# MIMXRT1064 register map
Vendor: nxp.com; File version: 1.0
CPU: CM7 r0p1, little endian, MPU, FPU, VTOR, 4 interrupt priority bits
Registers are 32-bit, read-write, reset 0x0 unless marked. A register's access mark holds for its fields unless they carry their own. Offsets are from the block's base; [hi:lo] are bit positions; {n}, {i} and the like mark numbered series; 'fields as' and 'values as' point back to an identical list.

## ADC_ETC
Base 0x403B0000
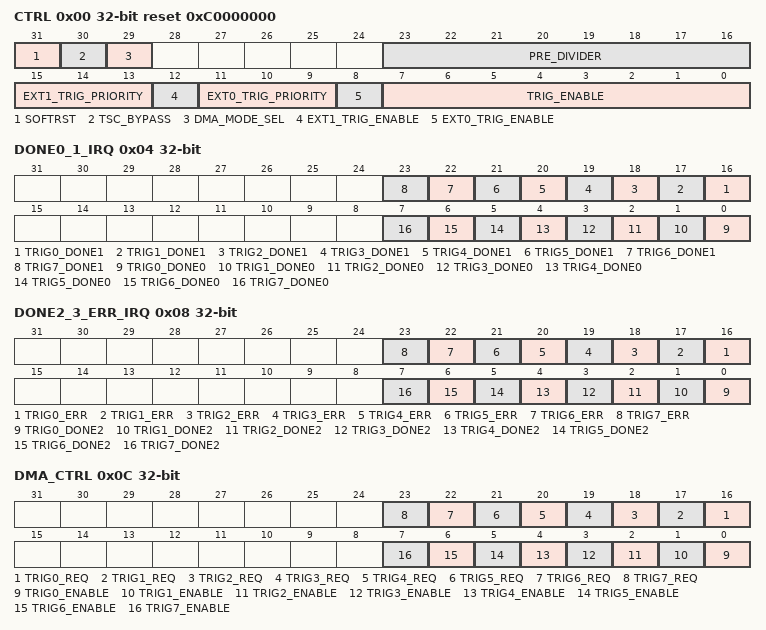
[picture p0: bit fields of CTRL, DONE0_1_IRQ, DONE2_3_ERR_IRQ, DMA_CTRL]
0x00 CTRL reset 0xC0000000 — ADC_ETC Global Control Register
  [31] SOFTRST — Software synchronous reset, active high.
    0=ADC_ETC works normally; 1=All registers inside ADC_ETC will be reset to the default value
  [30] TSC_BYPASS — TSC Bypass To use ADC2, this bit should be cleared.
    0=TSC not bypassed; 1=TSC is bypassed to ADC2, that means TSC will control ADC2 directly
  [29] DMA_MODE_SEL — Select the trigger type of the DMA_REQ.
    0=Trig DMA_REQ with latched signal, REQ will be cleared when ACK and source request cleared; 1=Trig DMA_REQ with pulsed signal, REQ will be cleared by ACK only
  [23:16] PRE_DIVIDER — Pre-divider for trig delay and interval
  [15:13] EXT1_TRIG_PRIORITY — External TSC1 trigger priority, 7 is highest priority, while 0 is lowest.
  [12] EXT1_TRIG_ENABLE — TSC1 TRIG enable register.
    0=disable external TSC1 trigger; 1=enable external TSC1 trigger
  [11:9] EXT0_TRIG_PRIORITY — External TSC0 trigger priority, 7 is highest priority, while 0 is lowest.
  [8] EXT0_TRIG_ENABLE — TSC0 TRIG enable register.
    0=disable external TSC0 trigger; 1=enable external TSC0 trigger
  [7:0] TRIG_ENABLE
    0=disable all 8 external XBAR triggers; 1=enable external XBAR trigger0; 2=enable external XBAR trigger1; 3=enable external XBAR trigger0 and trigger1; 255=enable all 8 external XBAR triggers
0x04 DONE0_1_IRQ write-1-clears — ETC DONE0 and DONE1 IRQ State Register
  [n+16] TRIG{n}_DONE1 write-1-clears (n=0..7) — TRIG{n} done1 interrupt detection.
    0=No TRIG{n}_DONE1 interrupt detected; 1=TRIG{n}_DONE1 interrupt detected
  [n] TRIG{n}_DONE0 write-1-clears (n=0..7) — TRIG{n} done0 interrupt detection.
    0=No TRIG{n}_DONE0 interrupt detected; 1=TRIG{n}_DONE0 interrupt detected
0x08 DONE2_3_ERR_IRQ — ETC DONE_2 and DONE_ERR IRQ State Register
  [n+16] TRIG{n}_ERR (n=0..7) — TRIG{n} error interrupt detection.
    0=No TRIG{n}_ERR interrupt detected; 1=TRIG{n}_ERR interrupt detected
  [n] TRIG{n}_DONE2 write-1-clears (n=0..7) — TRIG{n} done2 interrupt detection.
    0=No TRIG{n}_DONE2 interrupt detected; 1=TRIG{n}_DONE2 interrupt detected
0x0C DMA_CTRL — ETC DMA control Register
  [n+16] TRIG{n}_REQ write-1-clears (n=0..7) — Flag bit for DMA request
    0=TRIG{n}_REQ not detected; 1=TRIG{n}_REQ detected
  [n] TRIG{n}_ENABLE (n=0..7) — Enable DMA request when TRIG{n} done.
    0=TRIG{n} DMA request disabled; 1=TRIG{n} DMA request enabled
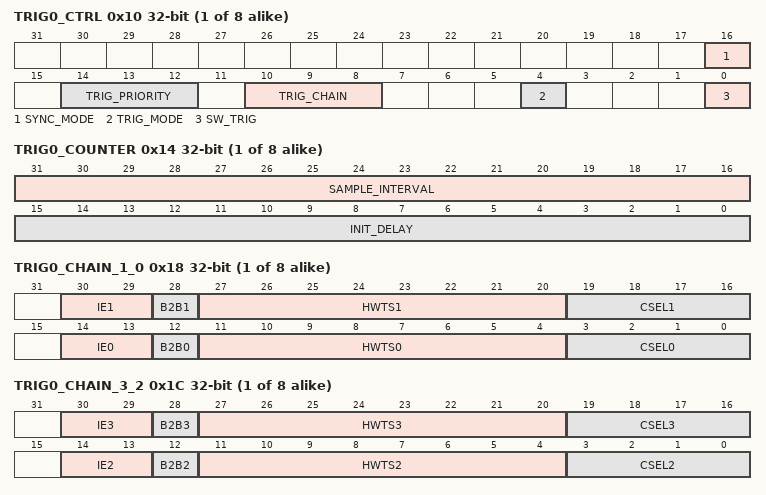
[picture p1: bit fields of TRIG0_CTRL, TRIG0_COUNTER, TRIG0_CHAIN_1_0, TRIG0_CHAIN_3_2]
{0x10+0x28*i} TRIG{i}_CTRL (i=0..7) — ETC_TRIG Control Register
  [16] SYNC_MODE — Trigger synchronization mode selection
    0=Synchronization mode disabled, TRIGa and TRIG(a+4) are triggered independently; 1=Synchronization mode enabled, TRIGa and TRIG(a+4) are triggered by TRIGa source synchronously
  [14:12] TRIG_PRIORITY — External trigger priority, 7 is highest priority, while 0 is lowest
  [10:8] TRIG_CHAIN — The number of segments inside the trigger chain of TRIGa.
    {v}=Trigger chain length is {v+1} (v=0..7)
  [4] TRIG_MODE — Trigger mode selection.
    0=Hardware trigger. The softerware trigger will be ignored.; 1=Software trigger. The hardware trigger will be ignored.
  [0] SW_TRIG — Software trigger. This field is self-clearing.
    0=No software trigger event generated; 1=Software trigger event generated
{0x14+0x28*i} TRIG{i}_COUNTER (i=0..7) — ETC_TRIG Counter Register
  [31:16] SAMPLE_INTERVAL — TRIGGER sampling interval counter
  [15:0] INIT_DELAY — TRIGGER initial delay counter. Initial_delay = (INIT_DELAY+1)*(PRE_DIVIDER+1)*ipg_clk
{0x18+0x28*i} TRIG{i}_CHAIN_1_0 (i=0..7) — ETC_TRIG Chain 0/1 Register
  [30:29] IE1 — Segment 1 done interrupt selection
    0=No interrupt when finished; 1=Generate interrupt on Done0 when Segment 1 finish; 2=Generate interrupt on Done1 when Segment 1 finish; 3=Generate interrupt on Done2 when Segment 1 finish
  [28] B2B1 — Segment 1 B2B
    0=Disable B2B. Wait until delay value defined by TRIG1_COUNTER[SAMPLE_INTERVAL] is reached; 1=Enable B2B. When Segment 0 finished (ADC COCO) then automatically trigger next ADC conversion, no need to wait until interval delay reached.
  [27:20] HWTS1 — Segment 1 HWTS ADC hardware trigger selection
    0=no trigger selected; 1=ADC TRIG0 selected; 2=ADC TRIG1 selected; 4=ADC TRIG2 selected; 8=ADC TRIG3 selected; 16=ADC TRIG4 selected; 32=ADC TRIG5 selected; 64=ADC TRIG6 selected; 128=ADC TRIG7 selected
  [19:16] CSEL1 — ADC channel selection
    {v}=ADC Channel {v} selected (v=0..15)
  [14:13] IE0 — Segment 0 done interrupt selection
    0=No interrupt when finished; 1=Generate interrupt on Done0 when segment 0 finish; 2=Generate interrupt on Done1 when segment 0 finish; 3=Generate interrupt on Done2 when segment 0 finish
  [12] B2B0 — Segment 0 B2B
    0=Disable B2B. Wait until delay value defined by TRIG0_COUNTER[SAMPLE_INTERVAL] is reached; 1=Enable B2B. When Segment 0 finished (ADC COCO) then automatically trigger next ADC conversion, no need to wait until interval delay reached.
  [11:4] HWTS0 — Segment 0 HWTS ADC hardware trigger selection
    values as HWTS1
  [3:0] CSEL0 — ADC channel selection
    {v}=ADC Channel {v} selected (v=0..15)
{0x1C+0x28*i} TRIG{i}_CHAIN_3_2 (i=0..7) — ETC_TRIG Chain 2/3 Register
  [30:29] IE3 — Segment 3 done interrupt selection
    0=No interrupt when finished; 1=Generate interrupt on Done0 when segment 3 finish; 2=Generate interrupt on Done1 when segment 3 finish; 3=Generate interrupt on Done2 when segment 3 finish
  [28] B2B3 — Segment 3 B2B
    0=Disable B2B. Wait until delay value defined by TRIG3_COUNTER[SAMPLE_INTERVAL] is reached; 1=Enable B2B. When Segment 0 finished (ADC COCO) then automatically trigger next ADC conversion, no need to wait until interval delay reached.
  [27:20] HWTS3 — Segment 3 HWTS ADC hardware trigger selection
    values as TRIG0_CHAIN_1_0.HWTS1
  [19:16] CSEL3 — ADC channel selection
    {v}=ADC Channel {v} selected (v=0..15)
  [14:13] IE2 — Segment 2 done interrupt selection
    0=No interrupt when finished; 1=Generate interrupt on Done0 when segment 2 finish; 2=Generate interrupt on Done1 when segment 2 finish; 3=Generate interrupt on Done2 when segment 2 finish
  [12] B2B2 — Segment 2 B2B
    0=Disable B2B. Wait until delay value defined by TRIG2_COUNTER[SAMPLE_INTERVAL] is reached; 1=Enable B2B. When Segment 0 finished (ADC COCO) then automatically trigger next ADC conversion, no need to wait until interval delay reached.
  [11:4] HWTS2 — Segment 2 HWTS ADC hardware trigger selection
    values as TRIG0_CHAIN_1_0.HWTS1
  [3:0] CSEL2 — ADC channel selection
    {v}=ADC Channel {v} selected (v=0..15)
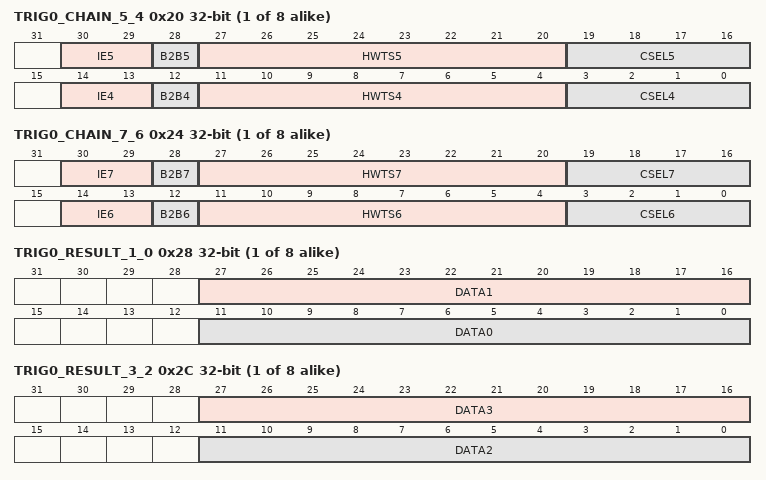
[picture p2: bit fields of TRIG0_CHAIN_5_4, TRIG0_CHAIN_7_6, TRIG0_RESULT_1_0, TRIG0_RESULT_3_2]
{0x20+0x28*i} TRIG{i}_CHAIN_5_4 (i=0..7) — ETC_TRIG Chain 4/5 Register
  [30:29] IE5 — Segment 5 done interrupt selection
    0=No interrupt when finished; 1=Generate interrupt on Done0 when segment 5 finish; 2=Generate interrupt on Done1 when segment 5 finish; 3=Generate interrupt on Done2 when segment 5 finish
  [28] B2B5 — Segment 5 B2B
    0=Disable B2B. Wait until delay value defined by TRIG5_COUNTER[SAMPLE_INTERVAL] is reached; 1=Enable B2B. When Segment 0 finished (ADC COCO) then automatically trigger next ADC conversion, no need to wait until interval delay reached.
  [27:20] HWTS5 — Segment 5 HWTS ADC hardware trigger selection
    values as TRIG0_CHAIN_1_0.HWTS1
  [19:16] CSEL5 — ADC channel selection
    {v}=ADC Channel {v} selected (v=0..15)
  [14:13] IE4 — Segment 4 done interrupt selection
    0=No interrupt when finished; 1=Generate interrupt on Done0 when segment 4 finish; 2=Generate interrupt on Done1 when segment 4 finish; 3=Generate interrupt on Done2 when segment 4 finish
  [12] B2B4 — Segment 4 B2B
    0=Disable B2B. Wait until delay value defined by TRIG4_COUNTER[SAMPLE_INTERVAL] is reached; 1=Enable B2B. When Segment 0 finished (ADC COCO) then automatically trigger next ADC conversion, no need to wait until interval delay reached.
  [11:4] HWTS4 — Segment 4 HWTS ADC hardware trigger selection
    values as TRIG0_CHAIN_1_0.HWTS1
  [3:0] CSEL4 — ADC channel selection
    {v}=ADC Channel {v} selected (v=0..15)
{0x24+0x28*i} TRIG{i}_CHAIN_7_6 (i=0..7) — ETC_TRIG Chain 6/7 Register
  [30:29] IE7 — Segment 7 done interrupt selection
    0=No interrupt when finished; 1=Generate interrupt on Done0 when segment 7 finish; 2=Generate interrupt on Done1 when segment 7 finish; 3=Generate interrupt on Done2 when segment 7 finish
  [28] B2B7 — Segment 7 B2B
    0=Disable B2B. Wait until delay value defined by TRIG7_COUNTER[SAMPLE_INTERVAL] is reached; 1=Enable B2B. When Segment 0 finished (ADC COCO) then automatically trigger next ADC conversion, no need to wait until interval delay reached.
  [27:20] HWTS7 — Segment 7 HWTS ADC hardware trigger selection
    values as TRIG0_CHAIN_1_0.HWTS1
  [19:16] CSEL7 — ADC channel selection
    {v}=ADC Channel {v} selected (v=0..15)
  [14:13] IE6 — Segment 6 done interrupt selection
    0=No interrupt when finished; 1=Generate interrupt on Done0 when segment 6 finish; 2=Generate interrupt on Done1 when segment 6 finish; 3=Generate interrupt on Done2 when segment 6 finish
  [12] B2B6 — Segment 6 B2B
    0=Disable B2B. Wait until delay value defined by TRIG6_COUNTER[SAMPLE_INTERVAL] is reached; 1=Enable B2B. When Segment 0 finished (ADC COCO) then automatically trigger next ADC conversion, no need to wait until interval delay reached.
  [11:4] HWTS6 — Segment 6 HWTS ADC hardware trigger selection
    values as TRIG0_CHAIN_1_0.HWTS1
  [3:0] CSEL6 — ADC channel selection
    {v}=ADC Channel {v} selected (v=0..15)
{0x28+0x28*i} TRIG{i}_RESULT_1_0 ro (i=0..7) — ETC_TRIG Result Data 1/0 Register
  [27:16] DATA1 — Result DATA1The sign bit from ADC result FIFO is ignored by ETC_TRIG result, so only 12-bit unsigned results is supported by ADC_ETC module
  [11:0] DATA0 — Result DATA0The sign bit from ADC result FIFO is ignored by ETC_TRIG result, so only 12-bit unsigned results is supported by ADC_ETC module
{0x2C+0x28*i} TRIG{i}_RESULT_3_2 ro (i=0..7) — ETC_TRIG Result Data 3/2 Register
  [27:16] DATA3 — Result DATA3The sign bit from ADC result FIFO is ignored by ETC_TRIG result, so only 12-bit unsigned results is supported by ADC_ETC module
  [11:0] DATA2 — Result DATA2The sign bit from ADC result FIFO is ignored by ETC_TRIG result, so only 12-bit unsigned results is supported by ADC_ETC module
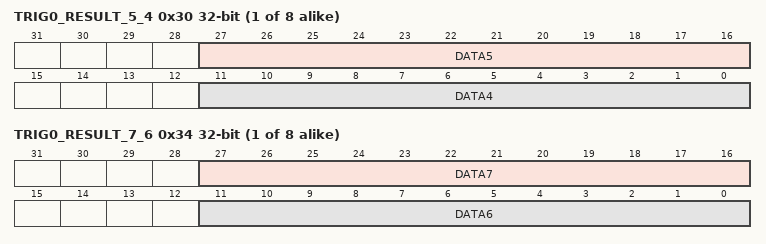
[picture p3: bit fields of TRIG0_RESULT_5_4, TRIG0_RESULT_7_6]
{0x30+0x28*i} TRIG{i}_RESULT_5_4 ro (i=0..7) — ETC_TRIG Result Data 5/4 Register
  [27:16] DATA5 — Result DATA5The sign bit from ADC result FIFO is ignored by ETC_TRIG result, so only 12-bit unsigned results is supported by ADC_ETC module
  [11:0] DATA4 — Result DATA4The sign bit from ADC result FIFO is ignored by ETC_TRIG result, so only 12-bit unsigned results is supported by ADC_ETC module
{0x34+0x28*i} TRIG{i}_RESULT_7_6 ro (i=0..7) — ETC_TRIG Result Data 7/6 Register
  [27:16] DATA7 — Result DATA7The sign bit from ADC result FIFO is ignored by ETC_TRIG result, so only 12-bit unsigned results is supported by ADC_ETC module
  [11:0] DATA6 — Result DATA6The sign bit from ADC result FIFO is ignored by ETC_TRIG result, so only 12-bit unsigned results is supported by ADC_ETC module
